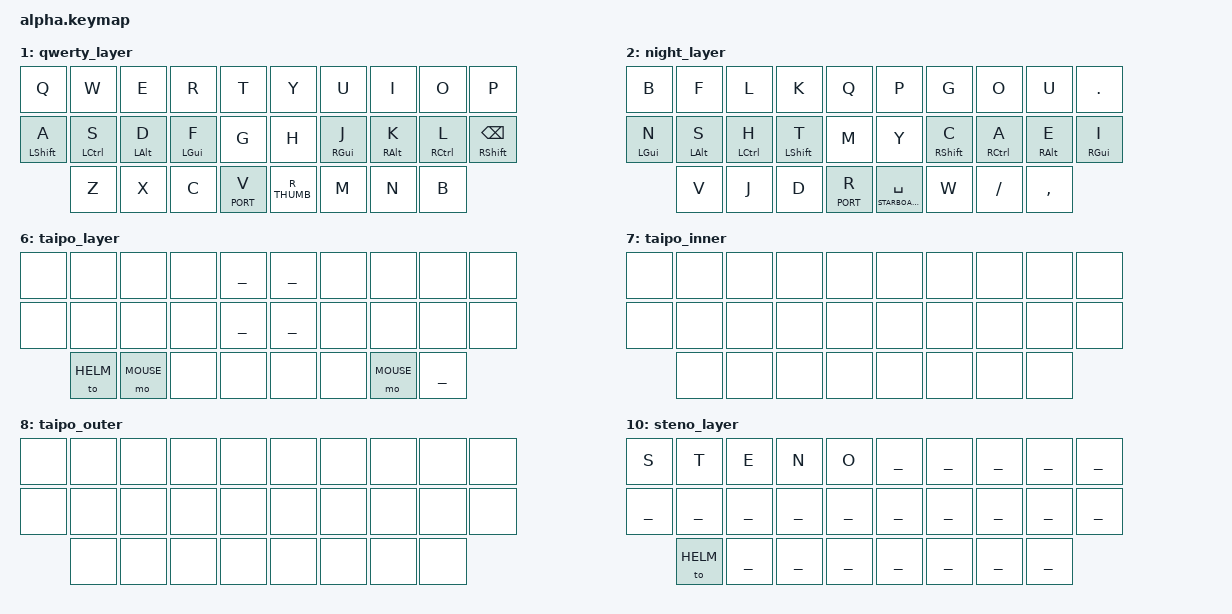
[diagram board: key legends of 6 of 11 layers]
#include "../../../key-labels/28.h"

#include "../../../base.keymap"

ZMK_LAYER(helm_layer,
    // ╭─────────────┬─────────────┬─────────────┬─────────────┬─────────────╮   ╭─────────────┬─────────────┬─────────────┬─────────────┬─────────────╮
         LEFT_HELM_UPPER_ROW________________________________________________       RIGHT_HELM_UPPER_ROW_______________________________________________
    // ├─────────────┼─────────────┼─────────────┼─────────────┼─────────────┤   ├─────────────┼─────────────┼─────────────┼─────────────┼─────────────┤
         LEFT_HELM_MIDDLE_ROW_______________________________________________       RIGHT_HELM_MIDDLE_ROW______________________________________________
    // ╰─────────────┼─────────────┼─────────────┼─────────────┼─────────────┤   ├─────────────┼─────────────┼─────────────┼─────────────┼─────────────╯
                       LEFT_HELM_LOWER_ROW____________________   L_THUMB           R_THUMB       RIGHT_HELM_LOWER_ROW___________________
    //               ╰─────────────┴─────────────┴─────────────┴─────────────╯   ╰─────────────┴─────────────┴─────────────┴─────────────╯
)
//ZMK_COMBO(helm_caps,  &caps_word, LM4 RM4, HELM, COMBO_TERM_SLOW)

ZMK_LAYER(qwerty_layer,
    // ╭─────────────┬─────────────┬─────────────┬─────────────┬─────────────╮   ╭─────────────┬─────────────┬─────────────┬─────────────┬─────────────╮
         &kp Q         &kp W         &kp E         &kp R         &kp T             &kp Y         &kp U         &kp I         &kp O         &kp P
    // ├─────────────┼─────────────┼─────────────┼─────────────┼─────────────┤   ├─────────────┼─────────────┼─────────────┼─────────────┼─────────────┤
         &hmls LSHFT A  &hml LCTRL S  &hml LALT D   &hml LGUI F   &kp G             &kp H         &hmr RGUI J   &hmr RALT K   &hmr RCTRL L  &hmrs RSHFT BSPC
    // ╰─────────────┼─────────────┼─────────────┼─────────────┼─────────────┤   ├─────────────┼─────────────┼─────────────┼─────────────┼─────────────╯
                       &kp Z         &kp X         &kp C         &ltp PORT V        R_THUMB       &kp M         &kp N         &kp B
    //               ╰─────────────┴─────────────┴─────────────┴─────────────╯   ╰─────────────┴─────────────┴─────────────┴─────────────╯
)

// Aptmak:
// v w f p b  j l u y '
// r s t h k  x n a i o
//[;]c g d[q][z]m , .[/]
//         _  e
// c+g=z, c+d=q, m+,=/, and ; on shifted ,
// Aptmak thumbs are layertap and spc/e
//#define PORT_SP     &ltp PORT SPC
//#define STARB_E     &lt STARBOARD E
// Aptmak combos
//ZMK_COMBO(amz,   &kp Z,         LB3 LB2,     APTMAK, COMBO_TERM_SLOW)
//ZMK_COMBO(amq,   &kp Q,         LB3 LB1,     APTMAK, COMBO_TERM_SLOW)
// Night thumbs
#define PORT_R      &ltp PORT R
#define STARB_SPC   &lt STARBOARD SPC
// Night combos
ZMK_COMBO(night_z,     &kp Z,      LB2 LB1, NIGHT, COMBO_TERM_SLOW)
ZMK_COMBO(night_x,     &kp X,      LB3 LB2, NIGHT, COMBO_TERM_SLOW)
ZMK_COMBO(night_sqt,   &kp SQT,    RB1 RB2, NIGHT, COMBO_TERM_SLOW)
ZMK_COMBO(night_semi,  &kp SEMI,   RB2 RB3, NIGHT, COMBO_TERM_SLOW)
//ZMK_COMBO(night_caps,  &caps_word, LM1 RM1, NIGHT, COMBO_TERM_SLOW)

ZMK_LAYER(night_layer,
    // b f l k q  p g o u .
    // n s h t m  y c a e i
    //[x]v j d[z][']w / ;[,]
    //         r  _
    // ╭─────────────┬─────────────┬─────────────┬─────────────┬─────────────╮   ╭─────────────┬─────────────┬─────────────┬─────────────┬─────────────╮
        &kp B         &kp F         &kp L         &kp K         &kp Q             &kp P         &kp G         &kp O         &kp U         &kp DOT
    // ├─────────────┼─────────────┼─────────────┼─────────────┼─────────────┤   ├─────────────┼─────────────┼─────────────┼─────────────┼─────────────┤
        &hml LGUI N   &hml LALT S   &hml LCTRL H  &hmls LSHFT T  &kp M             &kp Y         &hmrs RSHFT C  &hmr RCTRL A  &hmr RALT E   &hmr RGUI I
    // ╰─────────────┼─────────────┼─────────────┼─────────────┼─────────────┤   ├─────────────┼─────────────┼─────────────┼─────────────┼─────────────╯
                      &kp V         &kp J         &kp D         PORT_R            STARB_SPC     &kp W         &kp SLASH     &kp COMMA
    //               ╰─────────────┴─────────────┼─────────────┼─────────────╯   ╰─────────────┴─────────────┼─────────────┼─────────────╯
)

ZMK_LAYER(port_layer,
    // ╭─────────────┬─────────────┬─────────────┬─────────────┬─────────────╮   ╭─────────────┬─────────────┬─────────────┬─────────────┬─────────────╮
         LEFT_PORT_UPPER_ROW________________________________________________       RIGHT_PORT_UPPER_ROW_______________________________________________
    // ├─────────────┼─────────────┼─────────────┼─────────────┼─────────────┤   ├─────────────┼─────────────┼─────────────┼─────────────┼─────────────┤
         LEFT_PORT_MIDDLE_ROW_______________________________________________       RIGHT_PORT_MIDDLE_ROW______________________________________________
    // ╰─────────────┼─────────────┼─────────────┼─────────────┼─────────────┤   ├─────────────┼─────────────┼─────────────┼─────────────┼─────────────╯
                       LEFT_PORT_LOWER_ROW____________________   L_THUMB           R_THUMB       RIGHT_PORT_LOWER_ROW___________________
    //               ╰─────────────┴─────────────┴─────────────┴─────────────╯   ╰─────────────┴─────────────┴─────────────┴─────────────╯
)

ZMK_LAYER(starboard_layer,
    // ╭─────────────┬─────────────┬─────────────┬─────────────┬─────────────╮   ╭─────────────┬─────────────┬─────────────┬─────────────┬─────────────╮
         LEFT_STARBOARD_UPPER_ROW___________________________________________       RIGHT_STARBOARD_UPPER_ROW__________________________________________
    // ├─────────────┼─────────────┼─────────────┼─────────────┼─────────────┤   ├─────────────┼─────────────┼─────────────┼─────────────┼─────────────┤
         LEFT_STARBOARD_MIDDLE_ROW__________________________________________       RIGHT_STARBOARD_MIDDLE_ROW_________________________________________
    // ╰─────────────┼─────────────┼─────────────┼─────────────┼─────────────┤   ├─────────────┼─────────────┼─────────────┼─────────────┼─────────────╯
                       LEFT_STARBOARD_LOWER_ROW_______________   L_THUMB           R_THUMB       RIGHT_STARBOARD_LOWER_ROW______________
    //               ╰─────────────┴─────────────┴─────────────┴─────────────╯   ╰─────────────┴─────────────┴─────────────┴─────────────╯
)

ZMK_LAYER(aft_layer,
    // ╭─────────────┬─────────────┬─────────────┬─────────────┬─────────────╮   ╭─────────────┬─────────────┬─────────────┬─────────────┬─────────────╮
         LEFT_AFT_UPPER_ROW_________________________________________________       RIGHT_AFT_UPPER_ROW________________________________________________
    // ├─────────────┼─────────────┼─────────────┼─────────────┼─────────────┤   ├─────────────┼─────────────┼─────────────┼─────────────┼─────────────┤
         LEFT_AFT_MIDDLE_ROW________________________________________________       RIGHT_AFT_MIDDLE_ROW_______________________________________________
    // ╰─────────────┼─────────────┼─────────────┼─────────────┼─────────────┤   ├─────────────┼─────────────┼─────────────┼─────────────┼─────────────╯
                       LEFT_AFT_LOWER_ROW_____________________   L_THUMB           R_THUMB       RIGHT_AFT_LOWER_ROW____________________
    //               ╰─────────────┴─────────────┴─────────────┴─────────────╯   ╰─────────────┴─────────────┴─────────────┴─────────────╯
)

ZMK_LAYER(taipo_layer,
    // ╭─────────────┬─────────────┬─────────────┬─────────────┬─────────────╮   ╭─────────────┬─────────────┬─────────────┬─────────────┬─────────────╮
         &none         &none         &none         &none         ___               ___           &none         &none         &none         &none
    // ├─────────────┼─────────────┼─────────────┼─────────────┼─────────────┤   ├─────────────┼─────────────┼─────────────┼─────────────┼─────────────┤
         &none         &none         &none         &none         ___               ___           &none         &none         &none         &none
    // ╰─────────────┼─────────────┼─────────────┼─────────────┼─────────────┤   ├─────────────┼─────────────┼─────────────┼─────────────┼─────────────╯
                       &to HELM      &mo MOUSE     &none         &none             &none         &none         &mo MOUSE     ___
    //               ╰─────────────┴─────────────┼─────────────┼─────────────╯   ╰─────────────┴─────────────┼─────────────┼─────────────╯
)
// Add momentary mouse to both thumbs
ZMK_COMBO(Lmouse, &mo MOUSE, ITL OTL, TAIPO, COMBO_TERM_FAST)
ZMK_COMBO(Rmouse, &mo MOUSE, ITR OTR, TAIPO, COMBO_TERM_FAST)
ZMK_COMBO(Bmouse, &mo MOUSE, ITL ITR, TAIPO, COMBO_TERM_FAST)

ZMK_LAYER(taipo_inner,
    // ╭─────────────┬─────────────┬─────────────┬─────────────┬─────────────╮   ╭─────────────┬─────────────┬─────────────┬─────────────┬─────────────╮
         &none         &none         &none         &none         &none             &none         &none         &none         &none         &none
    // ├─────────────┼─────────────┼─────────────┼─────────────┼─────────────┤   ├─────────────┼─────────────┼─────────────┼─────────────┼─────────────┤
         &none         &none         &none         &none         &none             &none         &none         &none         &none         &none
    // ╰─────────────┼─────────────┼─────────────┼─────────────┼─────────────┤   ├─────────────┼─────────────┼─────────────┼─────────────┼─────────────╯
                       &none         &none         &none         &none             &none         &none         &none         &none
    //               ╰─────────────┴─────────────┼─────────────┼─────────────╯   ╰─────────────┴─────────────┼─────────────┼─────────────╯
)

ZMK_LAYER(taipo_outer,
    // ╭─────────────┬─────────────┬─────────────┬─────────────┬─────────────╮   ╭─────────────┬─────────────┬─────────────┬─────────────┬─────────────╮
         &none         &none         &none         &none         &none             &none         &none         &none         &none         &none
    // ├─────────────┼─────────────┼─────────────┼─────────────┼─────────────┤   ├─────────────┼─────────────┼─────────────┼─────────────┼─────────────┤
         &none         &none         &none         &none         &none             &none         &none         &none         &none         &none
    // ╰─────────────┼─────────────┼─────────────┼─────────────┼─────────────┤   ├─────────────┼─────────────┼─────────────┼─────────────┼─────────────╯
                       &none         &none         &none         &none             &none         &none         &none         &none
    //               ╰─────────────┴─────────────┼─────────────┼─────────────╯   ╰─────────────┴─────────────┼─────────────┼─────────────╯
)

ZMK_LAYER(mouse_layer,
    // ╭─────────────┬─────────────┬─────────────┬─────────────┬─────────────╮   ╭─────────────┬─────────────┬─────────────┬─────────────┬─────────────╮
         MOUSE_SCROLL_________________________________________   ___               ___           MOUSE_SCROLL_________________________________________
    // ├─────────────┼─────────────┼─────────────┼─────────────┼─────────────┤   ├─────────────┼─────────────┼─────────────┼─────────────┼─────────────┤
         MOUSE_MOVE___________________________________________   ___               ___           MOUSE_MOVE___________________________________________
    // ╰─────────────┼─────────────┼─────────────┼─────────────┼─────────────┤   ├─────────────┼─────────────┼─────────────┼─────────────┼─────────────╯
                       MOUSE_BUTTONS__________________________   &to TAIPO         &to HELM      MOUSE_BUTTONS__________________________
    //               ╰─────────────┴─────────────┼─────────────┼─────────────╯   ╰─────────────┴─────────────┼─────────────┼─────────────╯
)

ZMK_LAYER(steno_layer,
    // ╭─────────────┬─────────────┬─────────────┬─────────────┬─────────────╮   ╭─────────────┬─────────────┬─────────────┬─────────────┬─────────────╮
        &kp S         &kp T         &kp E         &kp N         &kp O             ___           ___           ___           ___           ___
    // ├─────────────┼─────────────┼─────────────┼─────────────┼─────────────┤   ├─────────────┼─────────────┼─────────────┼─────────────┼─────────────┤
        ___           ___           ___           ___           ___               ___           ___           ___           ___           ___
    // ╰─────────────┼─────────────┼─────────────┼─────────────┼─────────────┤   ├─────────────┼─────────────┼─────────────┼─────────────┼─────────────╯
                      &to HELM      ___           ___           ___               ___           ___           ___           ___
    //               ╰─────────────┴─────────────┼─────────────┼─────────────╯   ╰─────────────┴─────────────┼─────────────┼─────────────╯
)

/* vim: set tw=180 ft=c: */
